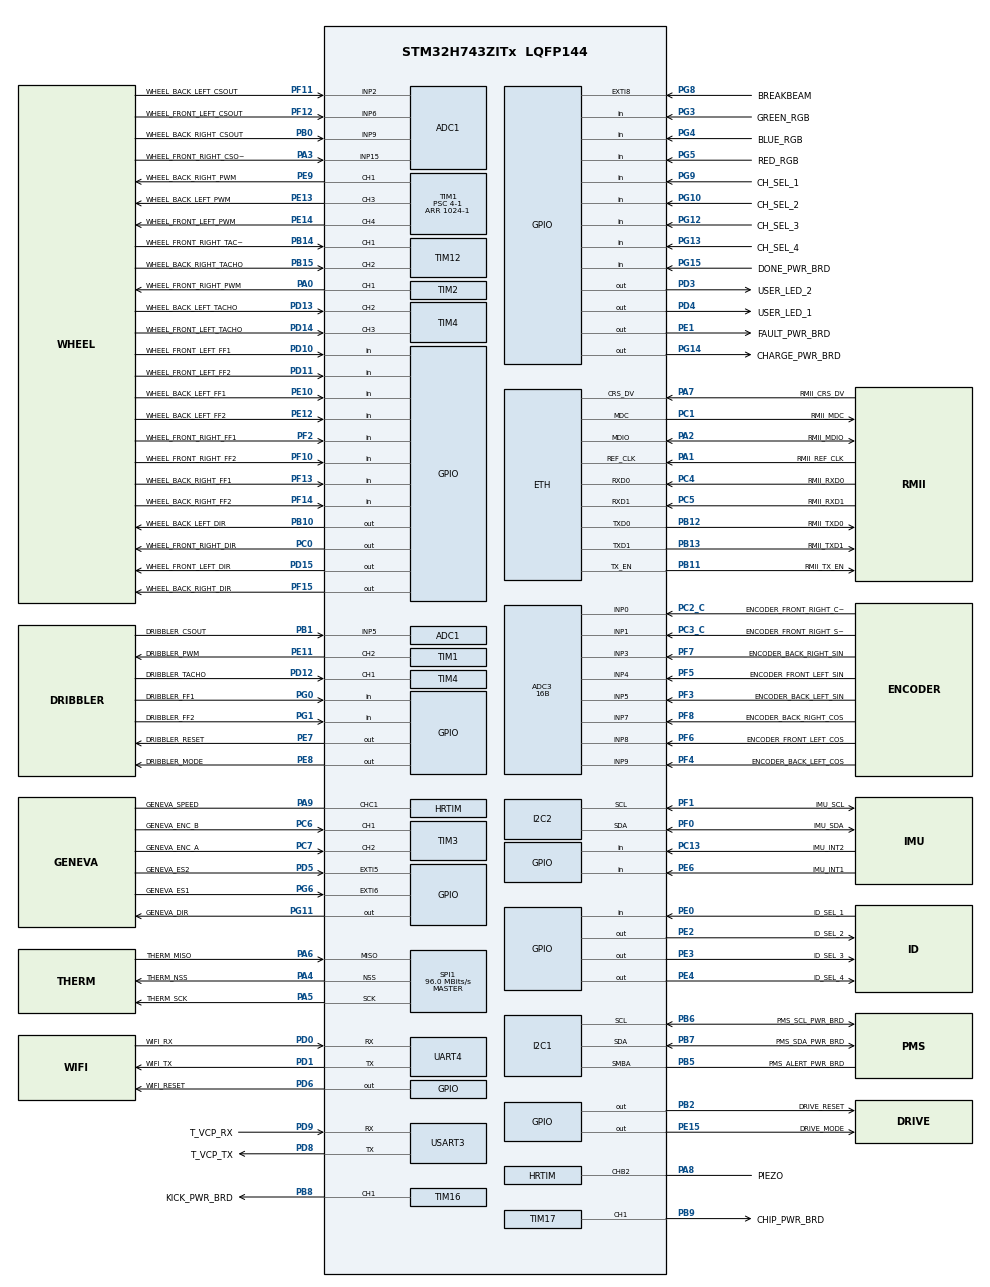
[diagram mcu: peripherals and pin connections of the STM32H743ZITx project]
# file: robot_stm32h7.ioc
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ADC1.Channel-1\#ChannelRegularConversion=ADC_CHANNEL_2
ADC1.ClockPrescaler=ADC_CLOCK_ASYNC_DIV256
ADC1.NbrOfConversionFlag=1
ADC1.OffsetNumber-1\#ChannelRegularConversion=ADC_OFFSET_NONE
ADC1.Rank-1\#ChannelRegularConversion=1
ADC1.SamplingTime-1\#ChannelRegularConversion=ADC_SAMPLETIME_1CYCLE_5
ADC1.master=1
ADC3.Channel-10\#ChannelRegularConversion=ADC_CHANNEL_9
ADC3.Channel-12\#ChannelRegularConversion=ADC_CHANNEL_VREFINT
ADC3.Channel-3\#ChannelRegularConversion=ADC_CHANNEL_0
ADC3.Channel-4\#ChannelRegularConversion=ADC_CHANNEL_1
ADC3.Channel-5\#ChannelRegularConversion=ADC_CHANNEL_3
ADC3.Channel-6\#ChannelRegularConversion=ADC_CHANNEL_4
ADC3.Channel-7\#ChannelRegularConversion=ADC_CHANNEL_5
ADC3.Channel-8\#ChannelRegularConversion=ADC_CHANNEL_7
ADC3.Channel-9\#ChannelRegularConversion=ADC_CHANNEL_8
ADC3.ClockPrescaler=ADC_CLOCK_ASYNC_DIV256
ADC3.ContinuousConvMode=ENABLE
ADC3.ConversionDataManagement=ADC_CONVERSIONDATA_DMA_CIRCULAR
ADC3.DiscontinuousConvMode=DISABLE
ADC3.EOCSelection=ADC_EOC_SEQ_CONV
ADC3.ExternalTrigConv=ADC_SOFTWARE_START
ADC3.NbrOfConversion=9
ADC3.NbrOfConversionFlag=1
ADC3.OffsetNumber-10\#ChannelRegularConversion=ADC_OFFSET_NONE
ADC3.OffsetNumber-12\#ChannelRegularConversion=ADC_OFFSET_NONE
ADC3.OffsetNumber-3\#ChannelRegularConversion=ADC_OFFSET_NONE
ADC3.OffsetNumber-4\#ChannelRegularConversion=ADC_OFFSET_NONE
ADC3.OffsetNumber-5\#ChannelRegularConversion=ADC_OFFSET_NONE
ADC3.OffsetNumber-6\#ChannelRegularConversion=ADC_OFFSET_NONE
ADC3.OffsetNumber-7\#ChannelRegularConversion=ADC_OFFSET_NONE
ADC3.OffsetNumber-8\#ChannelRegularConversion=ADC_OFFSET_NONE
ADC3.OffsetNumber-9\#ChannelRegularConversion=ADC_OFFSET_NONE
ADC3.OffsetSignedSaturation-10\#ChannelRegularConversion=DISABLE
ADC3.OffsetSignedSaturation-12\#ChannelRegularConversion=DISABLE
ADC3.OffsetSignedSaturation-4\#ChannelRegularConversion=DISABLE
ADC3.OffsetSignedSaturation-5\#ChannelRegularConversion=DISABLE
ADC3.OffsetSignedSaturation-6\#ChannelRegularConversion=DISABLE
ADC3.OffsetSignedSaturation-7\#ChannelRegularConversion=DISABLE
ADC3.OffsetSignedSaturation-8\#ChannelRegularConversion=DISABLE
ADC3.OffsetSignedSaturation-9\#ChannelRegularConversion=DISABLE
ADC3.Overrun=ADC_OVR_DATA_OVERWRITTEN
ADC3.Rank-10\#ChannelRegularConversion=8
ADC3.Rank-12\#ChannelRegularConversion=9
ADC3.Rank-3\#ChannelRegularConversion=1
ADC3.Rank-4\#ChannelRegularConversion=2
ADC3.Rank-5\#ChannelRegularConversion=3
ADC3.Rank-6\#ChannelRegularConversion=4
ADC3.Rank-7\#ChannelRegularConversion=5
ADC3.Rank-8\#ChannelRegularConversion=6
ADC3.Rank-9\#ChannelRegularConversion=7
ADC3.Resolution=ADC_RESOLUTION_16B
ADC3.SamplingTime-10\#ChannelRegularConversion=ADC_SAMPLETIME_64CYCLES_5
ADC3.SamplingTime-12\#ChannelRegularConversion=ADC_SAMPLETIME_64CYCLES_5
ADC3.SamplingTime-3\#ChannelRegularConversion=ADC_SAMPLETIME_64CYCLES_5
ADC3.SamplingTime-4\#ChannelRegularConversion=ADC_SAMPLETIME_64CYCLES_5
ADC3.SamplingTime-5\#ChannelRegularConversion=ADC_SAMPLETIME_64CYCLES_5
ADC3.SamplingTime-6\#ChannelRegularConversion=ADC_SAMPLETIME_64CYCLES_5
ADC3.SamplingTime-7\#ChannelRegularConversion=ADC_SAMPLETIME_64CYCLES_5
ADC3.SamplingTime-8\#ChannelRegularConversion=ADC_SAMPLETIME_64CYCLES_5
ADC3.SamplingTime-9\#ChannelRegularConversion=ADC_SAMPLETIME_64CYCLES_5
CORTEX_M7.AccessPermission-Cortex_Memory_Protection_Unit_Region0_Settings=MPU_REGION_FULL_ACCESS
CORTEX_M7.AccessPermission-Cortex_Memory_Protection_Unit_Region1_Settings=MPU_REGION_FULL_ACCESS
CORTEX_M7.BaseAddress-Cortex_Memory_Protection_Unit_Region0_Settings=0x30000000
CORTEX_M7.BaseAddress-Cortex_Memory_Protection_Unit_Region1_Settings=0x30024000
CORTEX_M7.CPU_DCache=Enabled
CORTEX_M7.CPU_ICache=Enabled
CORTEX_M7.DisableExec-Cortex_Memory_Protection_Unit_Region0_Settings=MPU_INSTRUCTION_ACCESS_DISABLE
CORTEX_M7.DisableExec-Cortex_Memory_Protection_Unit_Region1_Settings=MPU_INSTRUCTION_ACCESS_DISABLE
CORTEX_M7.Enable-Cortex_Memory_Protection_Unit_Region0_Settings=MPU_REGION_ENABLE
CORTEX_M7.Enable-Cortex_Memory_Protection_Unit_Region1_Settings=MPU_REGION_ENABLE
CORTEX_M7.Enable-Cortex_Memory_Protection_Unit_Region2_Settings=__NULL
CORTEX_M7.IsBufferable-Cortex_Memory_Protection_Unit_Region0_Settings=MPU_ACCESS_NOT_BUFFERABLE
CORTEX_M7.IsBufferable-Cortex_Memory_Protection_Unit_Region1_Settings=MPU_ACCESS_BUFFERABLE
CORTEX_M7.IsCacheable-Cortex_Memory_Protection_Unit_Region1_Settings=MPU_ACCESS_NOT_CACHEABLE
CORTEX_M7.IsShareable-Cortex_Memory_Protection_Unit_Region1_Settings=MPU_ACCESS_NOT_SHAREABLE
CORTEX_M7.MPU_Control=MPU_PRIVILEGED_DEFAULT
CORTEX_M7.Size-Cortex_Memory_Protection_Unit_Region0_Settings=MPU_REGION_SIZE_128KB
CORTEX_M7.Size-Cortex_Memory_Protection_Unit_Region1_Settings=MPU_REGION_SIZE_1KB
CORTEX_M7.TypeExtField-Cortex_Memory_Protection_Unit_Region0_Settings=MPU_TEX_LEVEL1
CORTEX_M7.TypeExtField-Cortex_Memory_Protection_Unit_Region1_Settings=MPU_TEX_LEVEL0
Dma.ADC3.1.Direction=DMA_PERIPH_TO_MEMORY
Dma.ADC3.1.EventEnable=DISABLE
Dma.ADC3.1.FIFOMode=DMA_FIFOMODE_DISABLE
Dma.ADC3.1.Instance=DMA1_Stream1
Dma.ADC3.1.MemDataAlignment=DMA_MDATAALIGN_HALFWORD
Dma.ADC3.1.MemInc=DMA_MINC_ENABLE
Dma.ADC3.1.Mode=DMA_CIRCULAR
Dma.ADC3.1.PeriphDataAlignment=DMA_PDATAALIGN_HALFWORD
Dma.ADC3.1.PeriphInc=DMA_PINC_DISABLE
Dma.ADC3.1.Polarity=HAL_DMAMUX_REQ_GEN_RISING
Dma.ADC3.1.Priority=DMA_PRIORITY_LOW
Dma.ADC3.1.RequestNumber=1
Dma.ADC3.1.SignalID=NONE
Dma.ADC3.1.SyncEnable=DISABLE
Dma.ADC3.1.SyncPolarity=HAL_DMAMUX_SYNC_NO_EVENT
Dma.ADC3.1.SyncRequestNumber=1
Dma.ADC3.1.SyncSignalID=NONE
Dma.Request0=UART4_RX
Dma.Request1=ADC3
Dma.UART4_RX.0.Direction=DMA_PERIPH_TO_MEMORY
Dma.UART4_RX.0.EventEnable=DISABLE
Dma.UART4_RX.0.FIFOMode=DMA_FIFOMODE_DISABLE
Dma.UART4_RX.0.Instance=DMA1_Stream0
Dma.UART4_RX.0.MemDataAlignment=DMA_MDATAALIGN_BYTE
Dma.UART4_RX.0.MemInc=DMA_MINC_ENABLE
Dma.UART4_RX.0.Mode=DMA_CIRCULAR
Dma.UART4_RX.0.PeriphDataAlignment=DMA_PDATAALIGN_BYTE
Dma.UART4_RX.0.PeriphInc=DMA_PINC_DISABLE
Dma.UART4_RX.0.Polarity=HAL_DMAMUX_REQ_GEN_RISING
Dma.UART4_RX.0.Priority=DMA_PRIORITY_LOW
Dma.UART4_RX.0.RequestNumber=1
Dma.UART4_RX.0.SignalID=NONE
Dma.UART4_RX.0.SyncEnable=DISABLE
Dma.UART4_RX.0.SyncPolarity=HAL_DMAMUX_SYNC_NO_EVENT
Dma.UART4_RX.0.SyncRequestNumber=1
Dma.UART4_RX.0.SyncSignalID=NONE
ETH.ETH_RX_DESC_CNT=0
ETH.ETH_TX_DESC_CNT=0
ETH.MediaInterface=HAL_ETH_RMII_MODE
ETH.RxBuffAddress=0x30040400
ETH.RxBuffLen=1024
ETH.TxDescAddress=0x30040180
FREERTOS.Queues01=RobotLogProtoQ,16,TbotsProto_RobotLog,0,Dynamic,NULL,NULL
FREERTOS.Tasks01=NetStartTask,24,1024,io_proto_multicast_startNetworkingTask,As weak,NULL,Static,NetStartTaskBuffer,NetStartTaskControlBlock;VisionMsgTask,24,1024,io_proto_multicast_listenerTask,As external,(void *)vision_msg_listener_profile,Static,VisionMsgTaskBuffer,VisionMsgTaskControlBlock;PrimMsgTask,24,1024,io_proto_multicast_listenerTask,As external,(void *)primitive_msg_listener_profile,Static,PrimMsgTaskBuffer,PrimMsgTaskControlBlock;RobotStatus,24,1024,io_robot_status_task,As external,(void*)robot_status_msg_sender_profile,Static,RobotStatusBuffer,RobotStatusControlBlock;RobotLogMsgSend,24,1024,io_proto_multicast_senderTask,As external,(void *)robot_log_msg_sender_profile,Static,RobotLogMsgSendBuffer,RobotLogMsgSendControlBlock;NetworkRobotLog,24,1024,io_network_logger_task,As external,(void*)robot_log_msg_sender_profile,Static,NetworkRobotLogBuffer,NetworkRobotLogControlBlock;RobotStatusSend,24,1024,io_proto_multicast_senderTask,As external,(void*)robot_status_msg_sender_profile,Static,RobotStatusSendBuffer,RobotStatusSendControlBlock;PrimExectuor,25,4096,io_primitive_executor_task,As external,NULL,Static,PrimExectuorBuffer,PrimExectuorControlBlock;PrimStarter,24,1024,io_primitive_starter_task,As external,(void *)primitive_msg_listener_profile,Static,PrimStarterBuffer,PrimStarterControlBlock;Vision,26,1024,io_vision_task,As external,(void *)vision_msg_listener_profile,Static,VisionBuffer,VisionControlBlock
FREERTOS.configMINIMAL_STACK_SIZE=1024
FREERTOS.configTOTAL_HEAP_SIZE=80720
I2C1.Timeout=0x000085B8
I2C1.Timing=0x307075B1
I2C2.Timing=0x307075B1
LWIP.BSP.number=1
LWIP.IP6_DEBUG=LWIP_DBG_ON
LWIP.LWIP_DBG_TYPES_ON=LWIP_DBG_OFF
LWIP.LWIP_DHCP=0
LWIP.LWIP_IGMP=1
LWIP.LWIP_IPV4=0
LWIP.LWIP_IPV6=1
LWIP.LWIP_MPU_COMPATIBLE=1
LWIP.LWIP_RAM_HEAP_POINTER=0x30020000
LWIP.LWIP_TCP=0
LWIP.LWIP_TCPIP_CORE_LOCKING=1
LWIP.LWIP_TCPIP_CORE_LOCKING_INPUT=1
LWIP.MEMP_MEM_INIT=1
LWIP.MEMP_MEM_MALLOC=0
LWIP.MEMP_NUM_MLD6_GROUP=10
LWIP.MEMP_NUM_NETBUF=10
LWIP.MEMP_NUM_UDP_PCB=10
LWIP.MEM_LIBC_MALLOC=1
LWIP.MEM_SIZE=16000
LWIP.NETIF_DEBUG=LWIP_DBG_OFF
LWIP.SLIP_DEBUG=LWIP_DBG_OFF
LWIP.UDP_DEBUG=LWIP_DBG_OFF
LWIP.Version=v2.1.2_Cube
LWIP0.BSP.STBoard=false
LWIP0.BSP.api=BSP_COMPONENT_DRIVER
LWIP0.BSP.component=LAN8742
LWIP0.BSP.i2caddr=0
LWIP0.BSP.instance=LAN8742
LWIP0.BSP.name=Driver_PHY
LWIP0.BSP.solution=LAN8742
Mcu.Family=STM32H7
Mcu.Name=STM32H743ZITx
Mcu.Package=LQFP144
NVIC.DMA1_Stream0_IRQn=true\:5\:0\:false\:false\:true\:true\:false\:true
NVIC.DMA1_Stream1_IRQn=true\:5\:0\:false\:false\:true\:true\:false\:true
NVIC.ETH_IRQn=true\:5\:0\:false\:false\:true\:true\:true\:true
NVIC.ETH_WKUP_IRQn=true\:5\:0\:false\:false\:true\:true\:true\:true
NVIC.PriorityGroup=NVIC_PRIORITYGROUP_4
NVIC.UART4_IRQn=true\:5\:0\:false\:false\:true\:true\:true\:true
NVIC.USART3_IRQn=true\:5\:0\:false\:false\:true\:true\:true\:true
PA0.GPIO_Label=WHEEL_FRONT_RIGHT_PWM
PA0.Signal=S_TIM2_CH1
PA1.GPIO_Label=RMII_REF_CLK
PA1.Mode=RMII
PA1.Signal=ETH_REF_CLK
PA13\ (JTMS/SWDIO).GPIO_Label=T_SWDIO
PA13\ (JTMS/SWDIO).Mode=Trace_Asynchronous_SW
PA13\ (JTMS/SWDIO).Signal=DEBUG_JTMS-SWDIO
PA14\ (JTCK/SWCLK).GPIO_Label=T_SWCLK
PA14\ (JTCK/SWCLK).Mode=Trace_Asynchronous_SW
PA14\ (JTCK/SWCLK).Signal=DEBUG_JTCK-SWCLK
PA2.GPIO_Label=RMII_MDIO
PA2.Mode=RMII
PA2.Signal=ETH_MDIO
PA3.GPIO_Label=WHEEL_FRONT_RIGHT_CSOUT
PA3.Signal=ADCx_INP15
PA4.GPIO_Label=THERM_NSS
PA4.Mode=NSS_Signal_Hard_Output
PA4.Signal=SPI1_NSS
PA5.GPIO_Label=THERM_SCK
PA5.Mode=RX_Only_Simplex_Unidirect_Master
PA5.Signal=SPI1_SCK
PA6.GPIO_Label=THERM_MISO
PA6.Mode=RX_Only_Simplex_Unidirect_Master
PA6.Signal=SPI1_MISO
PA7.GPIO_Label=RMII_CRS_DV
PA7.Mode=RMII
PA7.Signal=ETH_CRS_DV
PA8.GPIO_Label=PIEZO
PA8.Mode=Output_TB2
PA8.Signal=HRTIM_CHB2
PA9.GPIO_Label=GENEVA_SPEED
PA9.Mode=Output_TC1
PA9.Signal=HRTIM_CHC1
PB0.GPIO_Label=WHEEL_BACK_RIGHT_CSOUT
PB0.Signal=ADCx_INP9
PB1.GPIO_Label=DRIBBLER_CSOUT
PB1.Signal=ADCx_INP5
PB10.GPIO_Label=WHEEL_BACK_LEFT_DIR
PB10.Signal=GPIO_Output
PB11.GPIO_Label=RMII_TX_EN
PB11.Mode=RMII
PB11.Signal=ETH_TX_EN
PB12.GPIO_Label=RMII_TXD0
PB12.Mode=RMII
PB12.Signal=ETH_TXD0
PB13.GPIO_Label=RMII_TXD1
PB13.Mode=RMII
PB13.Signal=ETH_TXD1
PB14.GPIO_Label=WHEEL_FRONT_RIGHT_TACHO
PB14.Signal=S_TIM12_CH1
PB15.GPIO_Label=WHEEL_BACK_RIGHT_TACHO
PB15.Signal=S_TIM12_CH2
PB2.GPIO_Label=DRIVE_RESET
PB2.Signal=GPIO_Output
PB3\ (JTDO/TRACESWO).GPIO_Label=T_SWO
PB3\ (JTDO/TRACESWO).Mode=Trace_Asynchronous_SW
PB3\ (JTDO/TRACESWO).Signal=DEBUG_JTDO-SWO
PB5.GPIO_Label=PMS_ALERT_PWR_BRD
PB5.Mode=SMBus-Alert-mode
PB5.Signal=I2C1_SMBA
PB6.GPIO_Label=PMS_SCL_PWR_BRD
PB6.Mode=SMBus-Alert-mode
PB6.Signal=I2C1_SCL
PB7.GPIO_Label=PMS_SDA_PWR_BRD
PB7.Mode=SMBus-Alert-mode
PB7.Signal=I2C1_SDA
PB8.GPIO_Label=KICK_PWR_BRD
PB8.GPIO_PuPd=GPIO_PULLDOWN
PB8.Signal=S_TIM16_CH1
PB9.GPIO_Label=CHIP_PWR_BRD
PB9.GPIO_PuPd=GPIO_PULLDOWN
PB9.Signal=S_TIM17_CH1
PC0.GPIO_Label=WHEEL_FRONT_RIGHT_DIR
PC0.Signal=GPIO_Output
PC1.GPIO_Label=RMII_MDC
PC1.Mode=RMII
PC1.Signal=ETH_MDC
PC10.GPIO_Label=SD_DAT2
PC10.Signal=SDMMC1_D2
PC11.GPIO_Label=SD_DAT3
PC11.Signal=SDMMC1_D3
PC12.GPIO_Label=SD_CLK
PC12.Signal=SDMMC1_CK
PC13.GPIO_Label=IMU_INT2
PC13.Signal=GPIO_Input
PC14-OSC32_IN\ (OSC32_IN).GPIO_Label=PC14-OSC32_IN
PC14-OSC32_IN\ (OSC32_IN).Mode=LSE-External-Oscillator
PC14-OSC32_IN\ (OSC32_IN).Signal=RCC_OSC32_IN
PC15-OSC32_OUT\ (OSC32_OUT).GPIO_Label=PC15-OSC32_OUT
PC15-OSC32_OUT\ (OSC32_OUT).Mode=LSE-External-Oscillator
PC15-OSC32_OUT\ (OSC32_OUT).Signal=RCC_OSC32_OUT
PC2_C.GPIO_Label=ENCODER_FRONT_RIGHT_COS
PC2_C.Mode=IN0-Single-Ended
PC2_C.Signal=ADC3_INP0
PC3_C.GPIO_Label=ENCODER_FRONT_RIGHT_SIN
PC3_C.Mode=IN1-Single-Ended
PC3_C.Signal=ADC3_INP1
PC4.GPIO_Label=RMII_RXD0
PC4.Mode=RMII
PC4.Signal=ETH_RXD0
PC5.GPIO_Label=RMII_RXD1
PC5.Mode=RMII
PC5.Signal=ETH_RXD1
PC6.GPIO_Label=GENEVA_ENC_B
PC6.Signal=S_TIM3_CH1
PC7.GPIO_Label=GENEVA_ENC_A
PC7.Signal=S_TIM3_CH2
PC8.Signal=SDMMC1_D0
PC9.Signal=SDMMC1_D1
PD0.GPIO_Label=WIFI_RX
PD0.Mode=Asynchronous
PD0.Signal=UART4_RX
PD1.GPIO_Label=WIFI_TX
PD1.Mode=Asynchronous
PD1.Signal=UART4_TX
PD10.GPIO_Label=WHEEL_FRONT_LEFT_FF1
PD10.Signal=GPIO_Input
PD11.GPIO_Label=WHEEL_FRONT_LEFT_FF2
PD11.Signal=GPIO_Input
PD12.GPIO_Label=DRIBBLER_TACHO
PD12.Signal=S_TIM4_CH1
PD13.GPIO_Label=WHEEL_BACK_LEFT_TACHO
PD13.Signal=S_TIM4_CH2
PD14.GPIO_Label=WHEEL_FRONT_LEFT_TACHO
PD14.Signal=S_TIM4_CH3
PD15.GPIO_Label=WHEEL_FRONT_LEFT_DIR
PD15.Signal=GPIO_Output
PD2.GPIO_Label=SD_CMD
PD2.Signal=SDMMC1_CMD
PD3.GPIO_Label=USER_LED_2
PD3.Signal=GPIO_Output
PD4.GPIO_Label=USER_LED_1
PD4.Signal=GPIO_Output
PD5.GPIO_Label=GENEVA_ES2
PD5.Signal=GPXTI5
PD6.GPIO_Label=WIFI_RESET
PD6.Signal=GPIO_Output
PD8.GPIO_Label=T_VCP_TX
PD8.Mode=Asynchronous
PD8.Signal=USART3_TX
PD9.GPIO_Label=T_VCP_RX
PD9.Mode=Asynchronous
PD9.Signal=USART3_RX
PE0.GPIO_Label=ID_SEL_1
PE0.Signal=GPIO_Input
PE1.GPIO_Label=FAULT_PWR_BRD
PE1.GPIO_PuPd=GPIO_PULLUP
PE1.Signal=GPIO_Output
PE10.GPIO_Label=WHEEL_BACK_LEFT_FF1
PE10.Signal=GPIO_Input
PE11.GPIO_Label=DRIBBLER_PWM
PE11.Signal=S_TIM1_CH2
PE12.GPIO_Label=WHEEL_BACK_LEFT_FF2
PE12.Signal=GPIO_Input
PE13.GPIO_Label=WHEEL_BACK_LEFT_PWM
PE13.Signal=S_TIM1_CH3
PE14.GPIO_Label=WHEEL_FRONT_LEFT_PWM
PE14.Signal=S_TIM1_CH4
PE15.GPIO_Label=DRIVE_MODE
PE15.GPIO_ModeDefaultOutputPP=GPIO_MODE_OUTPUT_OD
PE15.GPIO_PuPd=GPIO_PULLUP
PE15.Signal=GPIO_Output
PE2.GPIO_Label=ID_SEL_2
PE2.Signal=GPIO_Output
PE3.GPIO_Label=ID_SEL_3
PE3.Signal=GPIO_Output
PE4.GPIO_Label=ID_SEL_4
PE4.Signal=GPIO_Output
PE6.GPIO_Label=IMU_INT1
PE6.Signal=GPIO_Input
PE7.GPIO_Label=DRIBBLER_RESET
PE7.Signal=GPIO_Output
PE8.GPIO_Label=DRIBBLER_MODE
PE8.Signal=GPIO_Output
PE9.GPIO_Label=WHEEL_BACK_RIGHT_PWM
PE9.Signal=S_TIM1_CH1
PF0.GPIO_Label=IMU_SDA
PF0.Mode=I2C
PF0.Signal=I2C2_SDA
PF1.GPIO_Label=IMU_SCL
PF1.Mode=I2C
PF1.Signal=I2C2_SCL
PF10.GPIO_Label=WHEEL_FRONT_RIGHT_FF2
PF10.Signal=GPIO_Input
PF11.GPIO_Label=WHEEL_BACK_LEFT_CSOUT
PF11.Mode=IN2-Single-Ended
PF11.Signal=ADC1_INP2
PF12.GPIO_Label=WHEEL_FRONT_LEFT_CSOUT
PF12.Mode=IN6-Single-Ended
PF12.Signal=ADC1_INP6
PF13.GPIO_Label=WHEEL_BACK_RIGHT_FF1
PF13.Signal=GPIO_Input
PF14.GPIO_Label=WHEEL_BACK_RIGHT_FF2
PF14.Signal=GPIO_Input
PF15.GPIO_Label=WHEEL_BACK_RIGHT_DIR
PF15.Signal=GPIO_Output
PF2.GPIO_Label=WHEEL_FRONT_RIGHT_FF1
PF2.Signal=GPIO_Input
PF3.GPIO_Label=ENCODER_BACK_LEFT_SIN
PF3.Mode=IN5-Single-Ended
PF3.Signal=ADC3_INP5
PF4.GPIO_Label=ENCODER_BACK_LEFT_COS
PF4.Mode=IN9-Single-Ended
PF4.Signal=ADC3_INP9
PF5.GPIO_Label=ENCODER_FRONT_LEFT_SIN
PF5.Mode=IN4-Single-Ended
PF5.Signal=ADC3_INP4
PF6.GPIO_Label=ENCODER_FRONT_LEFT_COS
PF6.Mode=IN8-Single-Ended
PF6.Signal=ADC3_INP8
PF7.GPIO_Label=ENCODER_BACK_RIGHT_SIN
PF7.Mode=IN3-Single-Ended
PF7.Signal=ADC3_INP3
PF8.GPIO_Label=ENCODER_BACK_RIGHT_COS
PF8.Mode=IN7-Single-Ended
PF8.Signal=ADC3_INP7
PF9.GPIO_Label=HV_SENSE_PWR_BRD
PF9.Signal=ADC3_INP2
PG0.GPIO_Label=DRIBBLER_FF1
PG0.Signal=GPIO_Input
PG1.GPIO_Label=DRIBBLER_FF2
PG1.Signal=GPIO_Input
PG10.GPIO_Label=CH_SEL_2
PG10.Signal=GPIO_Input
PG11.GPIO_Label=GENEVA_DIR
PG11.Signal=GPIO_Output
PG12.GPIO_Label=CH_SEL_3
PG12.Signal=GPIO_Input
PG13.GPIO_Label=CH_SEL_4
PG13.Signal=GPIO_Input
PG14.GPIO_Label=CHARGE_PWR_BRD
PG14.GPIO_PuPd=GPIO_PULLDOWN
PG14.Signal=GPIO_Output
PG15.GPIO_Label=DONE_PWR_BRD
PG15.Signal=GPIO_Input
PG3.GPIO_Label=GREEN_RGB
PG3.Signal=GPIO_Input
PG4.GPIO_Label=BLUE_RGB
PG4.Signal=GPIO_Input
PG5.GPIO_Label=RED_RGB
PG5.Signal=GPIO_Input
PG6.GPIO_Label=GENEVA_ES1
PG6.Signal=GPXTI6
PG8.GPIO_Label=BREAKBEAM
PG8.Signal=GPXTI8
PG9.GPIO_Label=CH_SEL_1
PG9.Signal=GPIO_Input
PH0-OSC_IN\ (PH0).GPIO_Label=PH0-OSC_IN
PH0-OSC_IN\ (PH0).Mode=HSE-External-Oscillator
PH0-OSC_IN\ (PH0).Signal=RCC_OSC_IN
PH1-OSC_OUT\ (PH1).GPIO_Label=PH1-OSC_OUT
PH1-OSC_OUT\ (PH1).Mode=HSE-External-Oscillator
PH1-OSC_OUT\ (PH1).Signal=RCC_OSC_OUT
ProjectManager.HeapSize=0x200
ProjectManager.StackSize=0x400
ProjectManager.TargetToolchain=Makefile
RCC.48MHZClocksFreq_Value=24000000
RCC.ADCFreq_Value=75000000
RCC.AHBFreq_Value=216000000
RCC.APB1CLKDivider=RCC_HCLK_DIV4
RCC.APB1Freq_Value=120000000
RCC.APB1TimFreq_Value=108000000
RCC.APB2CLKDivider=RCC_HCLK_DIV2
RCC.APB2Freq_Value=120000000
RCC.APB2TimFreq_Value=216000000
RCC.APB3Freq_Value=120000000
RCC.APB4Freq_Value=120000000
RCC.CortexFreq_Value=60000000
RCC.Cortex_Div=SYSTICK_CLKSOURCE_HCLK_DIV8
RCC.D1PPRE=RCC_APB3_DIV2
RCC.D2PPRE1=RCC_APB1_DIV2
RCC.D2PPRE2=RCC_APB2_DIV2
RCC.D3PPRE=RCC_APB4_DIV2
RCC.DIVM1=4
RCC.DIVM2=4
RCC.DIVM3=5
RCC.DIVN1=60
RCC.DIVN2=9
RCC.DIVN3=50
RCC.DIVQ1=5
RCC.DIVR1=4
RCC.HCLKFreq_Value=240000000
RCC.HPRE=RCC_HCLK_DIV2
RCC.HSE_VALUE=16000000
RCC.HSI_VALUE=64000000
RCC.PLL2FRACN=3072
RCC.PLLFRACN=0
RCC.PLLM=25
RCC.PLLMUL=RCC_PLL_MUL9
RCC.PLLN=432
RCC.PLLQ=9
RCC.PRESCALERUSB=RCC_USBCLKSOURCE_PLL_DIV1_5
RCC.PWR_Regulator_Voltage_Scale=PWR_REGULATOR_VOLTAGE_SCALE0
RCC.SYSCLKFreq_VALUE=480000000
RCC.SYSCLKSource=RCC_SYSCLKSOURCE_PLLCLK
RCC.SYSCLKSourceVirtual=RCC_SYSCLKSOURCE_PLLCLK
RCC.USBFreq_Value=192000000
RCC.VCOOutputFreq_Value=432000000
SH.ADCx_INP15.0=ADC1_INP15,IN15-Single-Ended
SH.ADCx_INP5.0=ADC1_INP5,IN5-Single-Ended
SH.ADCx_INP9.0=ADC1_INP9,IN9-Single-Ended
SH.S_TIM12_CH1.0=TIM12_CH1,Input_Capture1_from_TI1
SH.S_TIM12_CH2.0=TIM12_CH2,Input_Capture2_from_TI2
SH.S_TIM16_CH1.0=TIM16_CH1,PWM Generation1 CH1
SH.S_TIM17_CH1.0=TIM17_CH1,PWM Generation1 CH1
SH.S_TIM1_CH1.0=TIM1_CH1,PWM Generation1 CH1
SH.S_TIM1_CH2.0=TIM1_CH2,PWM Generation2 CH2
SH.S_TIM1_CH3.0=TIM1_CH3,PWM Generation3 CH3
SH.S_TIM1_CH4.0=TIM1_CH4,PWM Generation4 CH4
SH.S_TIM2_CH1.0=TIM2_CH1,PWM Generation1 CH1
SH.S_TIM3_CH1.0=TIM3_CH1,Input_Capture1_from_TI1
SH.S_TIM3_CH2.0=TIM3_CH2,Input_Capture2_from_TI2
SH.S_TIM4_CH1.0=TIM4_CH1,Input_Capture1_from_TI1
SH.S_TIM4_CH2.0=TIM4_CH2,Input_Capture2_from_TI2
SH.S_TIM4_CH3.0=TIM4_CH3,Input_Capture3_from_TI3
SPI1.BaudRatePrescaler=SPI_BAUDRATEPRESCALER_2
SPI1.CalculateBaudRate=96.0 MBits/s
SPI1.Direction=SPI_DIRECTION_2LINES_RXONLY
SPI1.Mode=SPI_MODE_MASTER
SPI1.VirtualNSS=VM_NSSHARD
SPI1.VirtualType=VM_MASTER
TIM1.AutoReloadPreload=TIM_AUTORELOAD_PRELOAD_ENABLE
TIM1.Channel-PWM\ Generation1\ CH1=TIM_CHANNEL_1
TIM1.Channel-PWM\ Generation2\ CH2=TIM_CHANNEL_2
TIM1.Channel-PWM\ Generation3\ CH3=TIM_CHANNEL_3
TIM1.Channel-PWM\ Generation4\ CH4=TIM_CHANNEL_4
TIM1.OCMode_PWM-PWM\ Generation1\ CH1=TIM_OCMODE_PWM2
TIM1.OCMode_PWM-PWM\ Generation2\ CH2=TIM_OCMODE_PWM2
TIM1.OCMode_PWM-PWM\ Generation3\ CH3=TIM_OCMODE_PWM2
TIM1.OCMode_PWM-PWM\ Generation4\ CH4=TIM_OCMODE_PWM2
TIM1.Period=1024-1
TIM1.Prescaler=4-1
TIM1.Pulse-PWM\ Generation1\ CH1=512
TIM1.Pulse-PWM\ Generation2\ CH2=512
TIM1.Pulse-PWM\ Generation3\ CH3=512
TIM1.Pulse-PWM\ Generation4\ CH4=512
TIM12.Channel-Input_Capture1_from_TI1=TIM_CHANNEL_1
TIM12.Channel-Input_Capture2_from_TI2=TIM_CHANNEL_2
TIM16.Channel=TIM_CHANNEL_1
TIM16.OCMode_PWM=TIM_OCMODE_PWM2
TIM16.Period=65536-1
TIM16.Prescaler=40-1
TIM16.Pulse=24000
TIM17.Channel=TIM_CHANNEL_1
TIM2.AutoReloadPreload=TIM_AUTORELOAD_PRELOAD_ENABLE
TIM2.Channel-PWM\ Generation1\ CH1=TIM_CHANNEL_1
TIM2.Period=1024-1
TIM2.Prescaler=4-1
TIM2.Pulse-PWM\ Generation1\ CH1=512
TIM3.Channel-Input_Capture1_from_TI1=TIM_CHANNEL_1
TIM3.Channel-Input_Capture2_from_TI2=TIM_CHANNEL_2
TIM4.Channel-Input_Capture1_from_TI1=TIM_CHANNEL_1
TIM4.Channel-Input_Capture2_from_TI2=TIM_CHANNEL_2
TIM4.Channel-Input_Capture3_from_TI3=TIM_CHANNEL_3
USART3.VirtualMode-Asynchronous=VM_ASYNC
VP_ADC3_Vref_Input.Mode=IN-Vrefint
VP_CRC_VS_CRC.Mode=CRC_Activate
VP_FREERTOS_VS_CMSIS_V2.Mode=CMSIS_V2
VP_LWIP_VS_Enabled.Mode=Enabled
VP_TIM16_VS_ClockSourceINT.Mode=Enable_Timer
VP_TIM16_VS_OPM.Mode=OPM_bit
VP_TIM17_VS_ClockSourceINT.Mode=Enable_Timer
board=NUCLEO-H743ZI

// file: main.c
/* USER CODE BEGIN Header */
/**
 ******************************************************************************
 * @file           : main.c
 * @brief          : Main program body
 ******************************************************************************
 * @attention
 *
 * <h2><center>&copy; Copyright (c) 2020 STMicroelectronics.
 * All rights reserved.</center></h2>
 *
 * This software component is licensed by ST under Ultimate Liberty license
 * SLA0044, the "License"; You may not use this file except in compliance with
 * the License. You may obtain a copy of the License at:
 *                             www.st.com/SLA0044
 *
 ******************************************************************************
 */
#pragma GCC diagnostic push
#pragma GCC diagnostic ignored "-Wsign-conversion"
/* USER CODE END Header */
#include "main.h"
#include "cmsis_os.h"
#include "adc.h"
#include "crc.h"
#include "dma.h"
#include "hrtim.h"
#include "hrtim.h"
#include "i2c.h"
#include "lwip.h"
#include "spi.h"
#include "tim.h"
#include "usart.h"
#include "gpio.h"

/* USER CODE BEGIN Includes */
#pragma GCC diagnostic pop

#include "firmware/app/logger/logger.h"
#include "firmware/app/primitives/primitive_manager.h"
#include "firmware/app/world/firmware_robot.h"
#include "firmware/app/world/firmware_world.h"
#include "firmware/boards/robot_stm32h7/io/charger.h"
#include "firmware/boards/robot_stm32h7/io/chicker.h"
#include "firmware/boards/robot_stm32h7/io/dribbler.h"
#include "firmware/boards/robot_stm32h7/io/drivetrain.h"
#include "firmware/boards/robot_stm32h7/io/power_monitor.h"
#include "firmware/boards/robot_stm32h7/io/primitive_executor.h"
#include "firmware/boards/robot_stm32h7/io/uart_logger.h"
#include "firmware/boards/robot_stm32h7/io/vision.h"
#include "firmware/shared/physics.h"
#include "shared/2021_robot_constants.h"

/* USER CODE END Includes */

/* USER CODE BEGIN PV */

ControllerState_t g_controller_state;

/* USER CODE END PV */

void SystemClock_Config(void);
void PeriphCommonClock_Config(void);
static void MPU_Config(void);
void MX_FREERTOS_Init(void);

/* USER CODE BEGIN 0 */

// TODO (#2082) remove this hack
float sys_now_float(void);
float sys_now_float(void)
{
    return (float)sys_now();
}

/* USER CODE END 0 */

int main(void)
{

  /* MPU Configuration--------------------------------------------------------*/
  MPU_Config();

  /* Enable I-Cache---------------------------------------------------------*/
  SCB_EnableICache();

  /* Enable D-Cache---------------------------------------------------------*/
  SCB_EnableDCache();

  /* MCU Configuration--------------------------------------------------------*/

  /* Reset of all peripherals, Initializes the Flash interface and the Systick. */
  HAL_Init();

  /* Configure the system clock */
  SystemClock_Config();

/* Configure the peripherals common clocks */
  PeriphCommonClock_Config();

  /* Initialize all configured peripherals */
  MX_GPIO_Init();
  MX_DMA_Init();
  MX_USART3_UART_Init();
  MX_ADC3_Init();
  MX_I2C1_SMBUS_Init();
  MX_I2C2_Init();
  MX_SPI1_Init();
  MX_ADC1_Init();
  MX_TIM1_Init();
  MX_UART4_Init();
  MX_CRC_Init();
  MX_TIM2_Init();
  MX_TIM16_Init();
  MX_TIM17_Init();
  MX_HRTIM_Init();
  MX_TIM3_Init();
  MX_TIM4_Init();
  MX_TIM12_Init();
  /* USER CODE BEGIN 2 */

    //              ---- Initialize App/IO Layers ----
    //
    // At this point the UART peripheral should be configured correctly
    // so we initialize the UART logger here so that we can see logs
    // from the initialization functions without having to be connected to a network
    io_uart_logger_init(&huart3);
    app_logger_init(0, &io_uart_logger_handleRobotLog);

    TLOG_DEBUG("Initializing I/O Layer");

    initIoDrivetrain();
    initIoNetworking();
    initIoPowerMonitor();

    // Setup the world that acts as the interface for the higher level firmware
    // (like primitives or the controller) to interface with the outside world
    WheelConstants_t wheel_constants = create2021WheelConstants();

    ForceWheel_t *front_left_wheel = app_force_wheel_create(
        io_drivetrain_applyForceFrontLeftWheel, io_drivetrain_getFrontLeftRpm,
        io_drivetrain_brakeFrontLeft, io_drivetrain_coastFrontLeft, wheel_constants);

    ForceWheel_t *front_right_wheel = app_force_wheel_create(
        io_drivetrain_applyForceFrontRightWheel, io_drivetrain_getFrontRightRpm,
        io_drivetrain_brakeFrontRight, io_drivetrain_coastFrontRight, wheel_constants);

    ForceWheel_t *back_right_wheel = app_force_wheel_create(
        io_drivetrain_applyForceBackRightWheel, io_drivetrain_getBackRightRpm,
        io_drivetrain_brakeBackRight, io_drivetrain_coastBackRight, wheel_constants);

    ForceWheel_t *back_left_wheel = app_force_wheel_create(
        io_drivetrain_applyForceBackLeftWheel, io_drivetrain_getBackLeftRpm,
        io_drivetrain_brakeBackLeft, io_drivetrain_coastBackLeft, wheel_constants);

    Charger_t *charger =
        app_charger_create(io_charger_charge, io_charger_discharge, io_charger_float);

    Chicker_t *chicker =
        app_chicker_create(io_chicker_kick, io_chicker_chip, io_chicker_enable_auto_kick,
                           io_chicker_enable_auto_chip, io_chicker_disable_auto_kick,
                           io_chicker_disable_auto_chip);

    Dribbler_t *dribbler = app_dribbler_create(io_dribbler_setSpeed, io_dribbler_coast,
                                               io_dribbler_getTemperature);

    const RobotConstants_t robot_constants = create2021RobotConstants();

    g_controller_state = (ControllerState_t){
        .last_applied_acceleration_x       = 0,
        .last_applied_acceleration_y       = 0,
        .last_applied_acceleration_angular = 0,
    };

    FirmwareRobot_t *robot = app_firmware_robot_force_wheels_create(
        charger, chicker, dribbler, io_vision_getRobotPositionX,
        io_vision_getRobotPositionY, io_vision_getRobotOrientation,
        io_vision_getRobotVelocityX, io_vision_getRobotVelocityY,
        io_vision_getRobotAngularVelocity, io_power_monitor_getBatteryVoltage,
        front_right_wheel, front_left_wheel, back_right_wheel, back_left_wheel,
        &g_controller_state, robot_constants);

    FirmwareBall_t *ball =
        app_firmware_ball_create(io_vision_getBallPositionX, io_vision_getBallPositionY,
                                 io_vision_getBallVelocityX, io_vision_getBallVelocityY);

    FirmwareWorld_t *world = app_firmware_world_create(robot, ball, sys_now_float);

    PrimitiveManager_t *primitive_manager = app_primitive_manager_create();

    io_primitive_executor_init(world, primitive_manager);

  /* USER CODE END 2 */

  /* Init scheduler */
  osKernelInitialize();  /* Call init function for freertos objects (in freertos.c) */
  MX_FREERTOS_Init();
  /* Start scheduler */
  osKernelStart();

  /* We should never get here as control is now taken by the scheduler */
  /* Infinite loop */
    while (1)
    {

    }
}

void SystemClock_Config(void)
{
  RCC_OscInitTypeDef RCC_OscInitStruct = {0};
  RCC_ClkInitTypeDef RCC_ClkInitStruct = {0};

  /** Supply configuration update enable
  */
  HAL_PWREx_ConfigSupply(PWR_LDO_SUPPLY);
  /** Configure the main internal regulator output voltage
  */
  __HAL_PWR_VOLTAGESCALING_CONFIG(PWR_REGULATOR_VOLTAGE_SCALE0);

  while(!__HAL_PWR_GET_FLAG(PWR_FLAG_VOSRDY)) {}
  /** Macro to configure the PLL clock source
  */
  __HAL_RCC_PLL_PLLSOURCE_CONFIG(RCC_PLLSOURCE_HSI);
  /** Initializes the RCC Oscillators according to the specified parameters
  * in the RCC_OscInitTypeDef structure.
  */
  RCC_OscInitStruct.OscillatorType = RCC_OSCILLATORTYPE_HSI;
  RCC_OscInitStruct.HSIState = RCC_HSI_DIV1;
  RCC_OscInitStruct.HSICalibrationValue = RCC_HSICALIBRATION_DEFAULT;
  RCC_OscInitStruct.PLL.PLLState = RCC_PLL_ON;
  RCC_OscInitStruct.PLL.PLLSource = RCC_PLLSOURCE_HSI;
  RCC_OscInitStruct.PLL.PLLM = 4;
  RCC_OscInitStruct.PLL.PLLN = 60;
  RCC_OscInitStruct.PLL.PLLP = 2;
  RCC_OscInitStruct.PLL.PLLQ = 5;
  RCC_OscInitStruct.PLL.PLLR = 4;
  RCC_OscInitStruct.PLL.PLLRGE = RCC_PLL1VCIRANGE_3;
  RCC_OscInitStruct.PLL.PLLVCOSEL = RCC_PLL1VCOWIDE;
  RCC_OscInitStruct.PLL.PLLFRACN = 0;
  if (HAL_RCC_OscConfig(&RCC_OscInitStruct) != HAL_OK)
  {
    Error_Handler();
  }
  /** Initializes the CPU, AHB and APB buses clocks
  */
  RCC_ClkInitStruct.ClockType = RCC_CLOCKTYPE_HCLK|RCC_CLOCKTYPE_SYSCLK
                              |RCC_CLOCKTYPE_PCLK1|RCC_CLOCKTYPE_PCLK2
                              |RCC_CLOCKTYPE_D3PCLK1|RCC_CLOCKTYPE_D1PCLK1;
  RCC_ClkInitStruct.SYSCLKSource = RCC_SYSCLKSOURCE_PLLCLK;
  RCC_ClkInitStruct.SYSCLKDivider = RCC_SYSCLK_DIV1;
  RCC_ClkInitStruct.AHBCLKDivider = RCC_HCLK_DIV2;
  RCC_ClkInitStruct.APB3CLKDivider = RCC_APB3_DIV2;
  RCC_ClkInitStruct.APB1CLKDivider = RCC_APB1_DIV2;
  RCC_ClkInitStruct.APB2CLKDivider = RCC_APB2_DIV2;
  RCC_ClkInitStruct.APB4CLKDivider = RCC_APB4_DIV2;

  if (HAL_RCC_ClockConfig(&RCC_ClkInitStruct, FLASH_LATENCY_4) != HAL_OK)
  {
    Error_Handler();
  }
}

void PeriphCommonClock_Config(void)
{
  RCC_PeriphCLKInitTypeDef PeriphClkInitStruct = {0};

  /** Initializes the peripherals clock
  */
  PeriphClkInitStruct.PeriphClockSelection = RCC_PERIPHCLK_ADC;
  PeriphClkInitStruct.PLL2.PLL2M = 4;
  PeriphClkInitStruct.PLL2.PLL2N = 9;
  PeriphClkInitStruct.PLL2.PLL2P = 2;
  PeriphClkInitStruct.PLL2.PLL2Q = 2;
  PeriphClkInitStruct.PLL2.PLL2R = 2;
  PeriphClkInitStruct.PLL2.PLL2RGE = RCC_PLL2VCIRANGE_3;
  PeriphClkInitStruct.PLL2.PLL2VCOSEL = RCC_PLL2VCOMEDIUM;
  PeriphClkInitStruct.PLL2.PLL2FRACN = 3072;
  PeriphClkInitStruct.AdcClockSelection = RCC_ADCCLKSOURCE_PLL2;
  if (HAL_RCCEx_PeriphCLKConfig(&PeriphClkInitStruct) != HAL_OK)
  {
    Error_Handler();
  }
}

/* MPU Configuration */

void MPU_Config(void)
{
  MPU_Region_InitTypeDef MPU_InitStruct = {0};

  /* Disables the MPU */
  HAL_MPU_Disable();
  /** Initializes and configures the Region and the memory to be protected
  */
  MPU_InitStruct.Enable = MPU_REGION_ENABLE;
  MPU_InitStruct.Number = MPU_REGION_NUMBER0;
  MPU_InitStruct.BaseAddress = 0x30000000;
  MPU_InitStruct.Size = MPU_REGION_SIZE_128KB;
  MPU_InitStruct.SubRegionDisable = 0x0;
  MPU_InitStruct.TypeExtField = MPU_TEX_LEVEL1;
  MPU_InitStruct.AccessPermission = MPU_REGION_FULL_ACCESS;
  MPU_InitStruct.DisableExec = MPU_INSTRUCTION_ACCESS_DISABLE;
  MPU_InitStruct.IsShareable = MPU_ACCESS_NOT_SHAREABLE;
  MPU_InitStruct.IsCacheable = MPU_ACCESS_NOT_CACHEABLE;
  MPU_InitStruct.IsBufferable = MPU_ACCESS_NOT_BUFFERABLE;

  HAL_MPU_ConfigRegion(&MPU_InitStruct);
  /** Initializes and configures the Region and the memory to be protected
  */
  MPU_InitStruct.Number = MPU_REGION_NUMBER1;
  MPU_InitStruct.BaseAddress = 0x30024000;
  MPU_InitStruct.Size = MPU_REGION_SIZE_1KB;
  MPU_InitStruct.TypeExtField = MPU_TEX_LEVEL0;
  MPU_InitStruct.IsBufferable = MPU_ACCESS_BUFFERABLE;

  HAL_MPU_ConfigRegion(&MPU_InitStruct);
  /* Enables the MPU */
  HAL_MPU_Enable(MPU_PRIVILEGED_DEFAULT);

}

void Error_Handler(void)
{
}

/************************ (C) COPYRIGHT STMicroelectronics *****END OF FILE****/

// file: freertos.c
/* USER CODE BEGIN Header */
/**
 ******************************************************************************
 * File Name          : freertos.c
 * Description        : Code for freertos applications
 ******************************************************************************
 * @attention
 *
 * <h2><center>&copy; Copyright (c) 2020 STMicroelectronics.
 * All rights reserved.</center></h2>
 *
 * This software component is licensed by ST under Ultimate Liberty license
 * SLA0044, the "License"; You may not use this file except in compliance with
 * the License. You may obtain a copy of the License at:
 *                             www.st.com/SLA0044
 *
 ******************************************************************************
 */
#pragma GCC diagnostic push
#pragma GCC diagnostic ignored "-Wsign-conversion"
/* USER CODE END Header */

#include "FreeRTOS.h"

#include "cmsis_os.h"
#include "main.h"
#include "task.h"

/* USER CODE BEGIN Includes */
#pragma GCC diagnostic pop
#include "firmware/app/logger/logger.h"
#include "firmware/boards/robot_stm32h7/io/drivetrain.h"
#include "firmware/boards/robot_stm32h7/io/network_logger.h"
#include "firmware/boards/robot_stm32h7/io/power_monitor.h"
#include "firmware/boards/robot_stm32h7/io/proto_multicast_communication_profile.h"
#include "firmware/boards/robot_stm32h7/io/proto_multicast_communication_tasks.h"
#include "firmware/boards/robot_stm32h7/io/ublox_odinw262_communicator.h"
#include "firmware/boards/robot_stm32h7/tim.h"
#include "firmware/boards/robot_stm32h7/usart.h"
#include "proto/robot_log_msg.nanopb.h"
#include "proto/robot_status_msg.nanopb.h"
#include "proto/tbots_software_msgs.nanopb.h"
#include "shared/constants.h"
/* USER CODE END Includes */

/* USER CODE BEGIN Variables */

ProtoMulticastCommunicationProfile_t *robot_status_msg_sender_profile;
ProtoMulticastCommunicationProfile_t *robot_log_msg_sender_profile;
ProtoMulticastCommunicationProfile_t *vision_msg_listener_profile;
ProtoMulticastCommunicationProfile_t *primitive_msg_listener_profile;

static TbotsProto_Vision vision_msg;
static TbotsProto_RobotStatus robot_status_msg;
static TbotsProto_RobotLog robot_log_msg;
static TbotsProto_Primitive primitive_msg;

/* USER CODE END Variables */
/* Definitions for NetStartTask */
osThreadId_t NetStartTaskHandle;
const osThreadAttr_t NetStartTask_attributes = {
    .name       = "NetStartTask",
    .stack_size = 1024 * 4,
    .priority   = (osPriority_t)osPriorityNormal,
};
/* Definitions for RobotStatusTask */
osThreadId_t RobotStatusTaskHandle;
const osThreadAttr_t RobotStatusTask_attributes = {
    .name       = "RobotStatusTask",
    .stack_size = 1024 * 4,
    .priority   = (osPriority_t)osPriorityNormal1,
};
/* Definitions for VisionMsgTask */
osThreadId_t VisionMsgTaskHandle;
const osThreadAttr_t VisionMsgTask_attributes = {
    .name       = "VisionMsgTask",
    .stack_size = 1024 * 4,
    .priority   = (osPriority_t)osPriorityNormal,
};
/* Definitions for PrimMsgTask */
osThreadId_t PrimMsgTaskHandle;
const osThreadAttr_t PrimMsgTask_attributes = {
    .name       = "PrimMsgTask",
    .stack_size = 1024 * 4,
    .priority   = (osPriority_t)osPriorityNormal,
};
/* Definitions for testMsgUpdate */
osThreadId_t testMsgUpdateHandle;
const osThreadAttr_t testMsgUpdate_attributes = {
    .name       = "testMsgUpdate",
    .stack_size = 1024 * 4,
    .priority   = (osPriority_t)osPriorityNormal,
};
/* Definitions for RobotLogMsgSend */
osThreadId_t RobotLogMsgSendHandle;
const osThreadAttr_t RobotLogMsgSend_attributes = {
    .name       = "RobotLogMsgSend",
    .stack_size = 1024 * 4,
    .priority   = (osPriority_t)osPriorityNormal,
};
/* Definitions for NetworkRobotLog */
osThreadId_t NetworkRobotLogHandle;
const osThreadAttr_t NetworkRobotLog_attributes = {
    .name       = "NetworkRobotLog",
    .stack_size = 1024 * 4,
    .priority   = (osPriority_t)osPriorityNormal,
};
/* Definitions for UbloxOdinTask */
osThreadId_t UbloxOdinTaskHandle;
const osThreadAttr_t UbloxOdinTask_attributes = {
    .name       = "UbloxOdinTask",
    .stack_size = 1024 * 4,
    .priority   = (osPriority_t)osPriorityNormal,
};
/* Definitions for RobotLogProtoQ */
osMessageQueueId_t RobotLogProtoQHandle;
const osMessageQueueAttr_t RobotLogProtoQ_attributes = {.name = "RobotLogProtoQ"};

void io_proto_multicast_startNetworkingTask(void *argument);
extern void io_proto_multicast_sender_task(void *argument);
extern void io_proto_multicast_listener_task(void *argument);
void test_msg_update(void *argument);
extern void io_network_logger_task(void *argument);
extern void io_ublox_odinw262_communicator_task(void *argument);

extern void MX_LWIP_Init(void);
void MX_FREERTOS_Init(void); /* (MISRA C 2004 rule 8.1) */

void MX_FREERTOS_Init(void)
{

    /* Create the queue(s) */
    /* creation of RobotLogProtoQ */
    RobotLogProtoQHandle =
        osMessageQueueNew(16, sizeof(TbotsProto_RobotLog), &RobotLogProtoQ_attributes);

    /* Create the thread(s) */
    /* creation of NetStartTask */
    NetStartTaskHandle = osThreadNew(io_proto_multicast_startNetworkingTask, NULL,
                                     &NetStartTask_attributes);

    /* creation of RobotStatusTask */
    RobotStatusTaskHandle =
        osThreadNew(io_proto_multicast_sender_task,
                    (void *)robot_status_msg_sender_profile, &RobotStatusTask_attributes);

    /* creation of VisionMsgTask */
    VisionMsgTaskHandle =
        osThreadNew(io_proto_multicast_listener_task, (void *)vision_msg_listener_profile,
                    &VisionMsgTask_attributes);

    /* creation of PrimMsgTask */
    PrimMsgTaskHandle =
        osThreadNew(io_proto_multicast_listener_task,
                    (void *)primitive_msg_listener_profile, &PrimMsgTask_attributes);

    /* creation of testMsgUpdate */
    testMsgUpdateHandle =
        osThreadNew(test_msg_update, (void *)robot_status_msg_sender_profile,
                    &testMsgUpdate_attributes);

    /* creation of RobotLogMsgSend */
    RobotLogMsgSendHandle =
        osThreadNew(io_proto_multicast_sender_task, (void *)robot_log_msg_sender_profile,
                    &RobotLogMsgSend_attributes);

    /* creation of NetworkRobotLog */
    NetworkRobotLogHandle =
        osThreadNew(io_network_logger_task, (void *)robot_log_msg_sender_profile,
                    &NetworkRobotLog_attributes);

    /* creation of UbloxOdinTask */
    UbloxOdinTaskHandle =
        osThreadNew(io_ublox_odinw262_communicator_task, NULL, &UbloxOdinTask_attributes);

}

__weak void io_proto_multicast_startNetworkingTask(void *argument)
{
    /* init code for LWIP */
    MX_LWIP_Init();
    for (;;)
    {
        osDelay(1);
    }
}

void test_msg_update(void *argument)
{
    /* USER CODE BEGIN test_msg_update */

    // TODO https://github.com/UBC-Thunderbots/Software/issues/1519
    // This is a placeholder task to test sending robot status NOT
    // associated with a ticket because how the robot status msgs will be
    // updated and sent is TBD
    ProtoMulticastCommunicationProfile_t *comm_profile =
        (ProtoMulticastCommunicationProfile_t *)argument;

    /* Infinite loop */
    for (;;)
    {
        io_proto_multicast_communication_profile_acquireLock(comm_profile);
        // TODO enable SNTP sys_now is currently only time since reset
        // https://github.com/UBC-Thunderbots/Software/issues/1518
        robot_status_msg.time_sent.epoch_timestamp_seconds = sys_now();

        robot_status_msg.power_status.battery_voltage =
            io_power_monitor_getBatteryVoltage();

        // We change the power status values randomly so that robot diagnostics
        // can "see" this robot on the network. This is a stopgap until we have
        // actual values for RobotStatus
        robot_status_msg.power_status.capacitor_voltage = (float)(sys_now() % 100);
        io_proto_multicast_communication_profile_releaseLock(comm_profile);
        io_proto_multicast_communication_profile_notifyEvents(comm_profile,
                                                              PROTO_UPDATED);
        TLOG_DEBUG("Power Monitor: %d",
                   (int)(robot_status_msg.power_status.battery_voltage * 1000.0f));
        // run loop at 100hz
        osDelay((unsigned int)MILLISECONDS_PER_SECOND / 10);
    }
    /* USER CODE END test_msg_update */
}

/* USER CODE BEGIN Application */
void initIoNetworking(void)
{
    // TODO channel and robot_id need to be hooked up to the dials on the robot, when
    // available https://github.com/UBC-Thunderbots/Software/issues/1517
    unsigned short int channel = 0;

    // initialize multicast communication
    io_proto_multicast_communication_init(NETWORK_TIMEOUT_MS);

    primitive_msg_listener_profile = io_proto_multicast_communication_profile_create(
        "primitive_msg_listener_profile", ROBOT_MULTICAST_CHANNELS[channel],
        PRIMITIVE_PORT, &primitive_msg, TbotsProto_Primitive_fields,
        MAXIMUM_TRANSFER_UNIT_BYTES);

    vision_msg_listener_profile = io_proto_multicast_communication_profile_create(
        "vision_msg_listener_profile", ROBOT_MULTICAST_CHANNELS[channel], VISION_PORT,
        &vision_msg, TbotsProto_Vision_fields, MAXIMUM_TRANSFER_UNIT_BYTES);

    robot_status_msg_sender_profile = io_proto_multicast_communication_profile_create(
        "robot_status_msg_sender", ROBOT_MULTICAST_CHANNELS[channel], ROBOT_STATUS_PORT,
        &robot_status_msg, TbotsProto_RobotStatus_fields, MAXIMUM_TRANSFER_UNIT_BYTES);

    robot_log_msg_sender_profile = io_proto_multicast_communication_profile_create(
        "robot_log_msg_sender", ROBOT_MULTICAST_CHANNELS[channel], ROBOT_LOGS_PORT,
        &robot_log_msg, TbotsProto_RobotLog_fields, MAXIMUM_TRANSFER_UNIT_BYTES);

    // TODO (#2064) mainboard rev 2.0 doens't have a reset pin for the u-blox chip
    // so we can't enable the communicator. Uncomment this for mainboard rev 2.1
    // which should fix this issue.
    //
    // GpioPin_t *ublox_reset_pin =
    //     io_gpio_pin_create(ublox_reset_GPIO_Port, ublox_reset_Pin, ACTIVE_LOW);
    // io_ublox_odinw262_communicator_init(&huart8, ublox_reset_pin, 5);

    // initialize network logger
    io_network_logger_init(RobotLogProtoQHandle);
}

void initIoDrivetrain(void)
{
    // TODO (#2063) the motor driver pins are not wired correctly on mainboard rev2.0
    // We will not be trying to drive any motors until we have mainboard rev2.1 which
    // addresses the board issues.
}

void initPowerMonitor(void)
{
    io_power_monitor_init(I2C1, INA226_ADDRESS,
                          INA226_MODE_CONT_SHUNT_AND_BUS | INA226_VBUS_140uS |
                              INA226_VBUS_140uS | INA226_AVG_1024);
}

/* USER CODE END Application */

/************************ (C) COPYRIGHT STMicroelectronics *****END OF FILE****/
